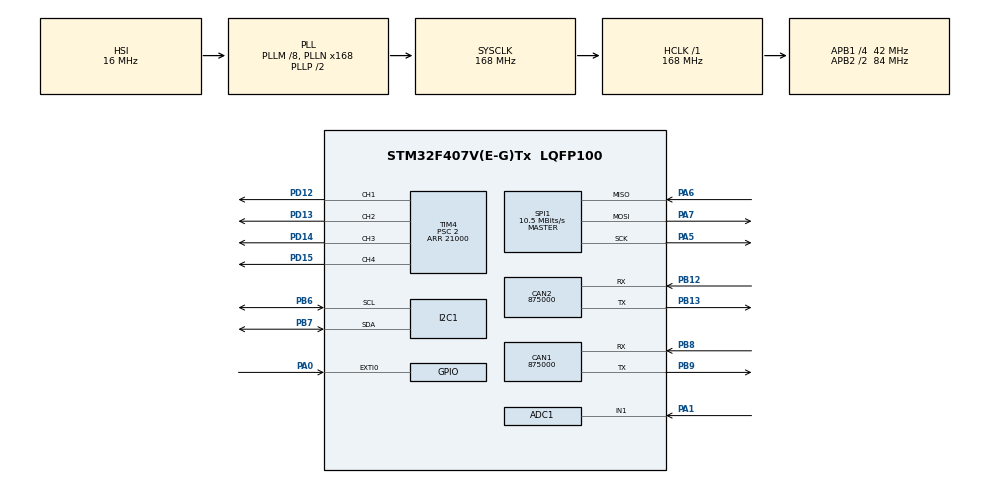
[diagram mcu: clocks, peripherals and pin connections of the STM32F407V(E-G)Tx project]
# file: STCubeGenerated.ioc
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ADC1.Channel-0\#ChannelRegularConversion=ADC_CHANNEL_1
ADC1.NbrOfConversionFlag=1
ADC1.Rank-0\#ChannelRegularConversion=1
ADC1.SamplingTime-0\#ChannelRegularConversion=ADC_SAMPLETIME_3CYCLES
ADC1.master=1
CAN1.BS1=CAN_BS1_1TQ
CAN1.BS2=CAN_BS2_1TQ
CAN1.CalculateBaudRate=875000
CAN1.CalculateTimeBit=1142.85
CAN1.CalculateTimeQuantum=380.95238095238096
CAN2.BS1=CAN_BS1_1TQ
CAN2.BS2=CAN_BS2_1TQ
CAN2.CalculateBaudRate=875000
CAN2.CalculateTimeBit=1142.85
CAN2.CalculateTimeQuantum=380.95238095238096
Mcu.Family=STM32F4
Mcu.Name=STM32F407V(E-G)Tx
Mcu.Package=LQFP100
NVIC.CAN1_RX0_IRQn=true\:0\:0\:false\:false\:true\:true\:true
NVIC.CAN1_RX1_IRQn=true\:0\:0\:false\:false\:true\:true\:true
NVIC.CAN2_RX0_IRQn=true\:0\:0\:false\:false\:true\:true\:true
NVIC.CAN2_RX1_IRQn=true\:0\:0\:false\:false\:true\:true\:true
NVIC.EXTI0_IRQn=true\:0\:0\:false\:false\:true\:true\:true
NVIC.PriorityGroup=NVIC_PRIORITYGROUP_4
PA0-WKUP.Signal=GPXTI0
PA1.Signal=ADCx_IN1
PA5.Mode=Full_Duplex_Master
PA5.Signal=SPI1_SCK
PA6.Mode=Full_Duplex_Master
PA6.Signal=SPI1_MISO
PA7.Mode=Full_Duplex_Master
PA7.Signal=SPI1_MOSI
PB12.Mode=CAN_Activate
PB12.Signal=CAN2_RX
PB13.Mode=CAN_Activate
PB13.Signal=CAN2_TX
PB6.Mode=I2C
PB6.Signal=I2C1_SCL
PB7.Mode=I2C
PB7.Signal=I2C1_SDA
PB8.Mode=CAN_Activate
PB8.Signal=CAN1_RX
PB9.Mode=CAN_Activate
PB9.Signal=CAN1_TX
PD12.Signal=S_TIM4_CH1
PD13.Signal=S_TIM4_CH2
PD14.Signal=S_TIM4_CH3
PD15.Signal=S_TIM4_CH4
ProjectManager.HeapSize=0x200
ProjectManager.StackSize=0x400
ProjectManager.TargetToolchain=MDK-ARM V5
RCC.48MHZClocksFreq_Value=84000000
RCC.AHBFreq_Value=168000000
RCC.APB1CLKDivider=RCC_HCLK_DIV4
RCC.APB1Freq_Value=42000000
RCC.APB1TimFreq_Value=84000000
RCC.APB2CLKDivider=RCC_HCLK_DIV2
RCC.APB2Freq_Value=84000000
RCC.APB2TimFreq_Value=168000000
RCC.CortexFreq_Value=168000000
RCC.HCLKFreq_Value=168000000
RCC.HSE_VALUE=25000000
RCC.HSI_VALUE=16000000
RCC.LSE_VALUE=32768
RCC.PLLM=8
RCC.PLLN=168
RCC.SYSCLKFreq_VALUE=168000000
RCC.SYSCLKSource=RCC_SYSCLKSOURCE_PLLCLK
RCC.VCOOutputFreq_Value=336000000
SH.ADCx_IN1.0=ADC1_IN1,IN1
SH.S_TIM4_CH1.0=TIM4_CH1,PWM Generation1 CH1
SH.S_TIM4_CH2.0=TIM4_CH2,PWM Generation2 CH2
SH.S_TIM4_CH3.0=TIM4_CH3,PWM Generation3 CH3
SH.S_TIM4_CH4.0=TIM4_CH4,Output Compare4 CH4
SPI1.BaudRatePrescaler=SPI_BAUDRATEPRESCALER_8
SPI1.CalculateBaudRate=10.5 MBits/s
SPI1.Direction=SPI_DIRECTION_2LINES
SPI1.Mode=SPI_MODE_MASTER
SPI1.VirtualType=VM_MASTER
TIM4.Channel-Output\ Compare4\ CH4=TIM_CHANNEL_4
TIM4.Channel-PWM\ Generation1\ CH1=TIM_CHANNEL_1
TIM4.Channel-PWM\ Generation2\ CH2=TIM_CHANNEL_2
TIM4.Channel-PWM\ Generation3\ CH3=TIM_CHANNEL_3
TIM4.Period=21000
TIM4.Prescaler=2
board=custom

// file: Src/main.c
/* USER CODE BEGIN Header */
/**
  ******************************************************************************
  * @file           : main.c
  * @brief          : Main program body
  ******************************************************************************
  * @attention
  *
  * <h2><center>&copy; Copyright (c) 2021 STMicroelectronics.
  * All rights reserved.</center></h2>
  *
  * This software component is licensed by ST under BSD 3-Clause license,
  * the "License"; You may not use this file except in compliance with the
  * License. You may obtain a copy of the License at:
  *                        opensource.org/licenses/BSD-3-Clause
  *
  ******************************************************************************
  */
/* USER CODE END Header */
#include "main.h"

/* USER CODE BEGIN Includes */
#include "HWDef.h"

/* USER CODE END Includes */

static ADC_HandleTypeDef hadc1;

static CAN_HandleTypeDef hcan1;
static CAN_HandleTypeDef hcan2;

static I2C_HandleTypeDef hi2c1;

static SPI_HandleTypeDef hspi1;

static TIM_HandleTypeDef htim4;

void SystemClock_Config(void);
static void MX_GPIO_Init(void);
static void MX_ADC1_Init(void);
static void MX_CAN1_Init(void);
static void MX_CAN2_Init(void);
static void MX_I2C1_Init(void);
static void MX_SPI1_Init(void);
static void MX_TIM4_Init(void);

/* USER CODE BEGIN 0 */
void app_main(void *argument) {

  while (1)
    ;
}

/* USER CODE END 0 */

int main(void)
{

  /* MCU Configuration--------------------------------------------------------*/

  /* Reset of all peripherals, Initializes the Flash interface and the Systick. */
  HAL_Init();

  /* Configure the system clock */
  SystemClock_Config();

  /* USER CODE BEGIN SysInit */
	osKernelInitialize();                 // Initialize CMSIS-RTOS
  osThreadNew(app_main, NULL, NULL);    // Create application main thread
	osThreadSetPriority(app_main,osPriorityNormal);
  osKernelStart();

  /* USER CODE END SysInit */

  /* Initialize all configured peripherals */
  MX_GPIO_Init();
  MX_ADC1_Init();
  MX_CAN1_Init();
  MX_CAN2_Init();
  MX_I2C1_Init();
  MX_SPI1_Init();
  MX_TIM4_Init();

  /* Infinite loop */
  while (1)
  {

  }
}

void SystemClock_Config(void)
{
  RCC_OscInitTypeDef RCC_OscInitStruct = {0};
  RCC_ClkInitTypeDef RCC_ClkInitStruct = {0};

  /** Configure the main internal regulator output voltage
  */
  __HAL_RCC_PWR_CLK_ENABLE();
  __HAL_PWR_VOLTAGESCALING_CONFIG(PWR_REGULATOR_VOLTAGE_SCALE1);
  /** Initializes the RCC Oscillators according to the specified parameters
  * in the RCC_OscInitTypeDef structure.
  */
  RCC_OscInitStruct.OscillatorType = RCC_OSCILLATORTYPE_HSI;
  RCC_OscInitStruct.HSIState = RCC_HSI_ON;
  RCC_OscInitStruct.HSICalibrationValue = RCC_HSICALIBRATION_DEFAULT;
  RCC_OscInitStruct.PLL.PLLState = RCC_PLL_ON;
  RCC_OscInitStruct.PLL.PLLSource = RCC_PLLSOURCE_HSI;
  RCC_OscInitStruct.PLL.PLLM = 8;
  RCC_OscInitStruct.PLL.PLLN = 168;
  RCC_OscInitStruct.PLL.PLLP = RCC_PLLP_DIV2;
  RCC_OscInitStruct.PLL.PLLQ = 4;
  if (HAL_RCC_OscConfig(&RCC_OscInitStruct) != HAL_OK)
  {
    Error_Handler();
  }
  /** Initializes the CPU, AHB and APB buses clocks
  */
  RCC_ClkInitStruct.ClockType = RCC_CLOCKTYPE_HCLK|RCC_CLOCKTYPE_SYSCLK
                              |RCC_CLOCKTYPE_PCLK1|RCC_CLOCKTYPE_PCLK2;
  RCC_ClkInitStruct.SYSCLKSource = RCC_SYSCLKSOURCE_PLLCLK;
  RCC_ClkInitStruct.AHBCLKDivider = RCC_SYSCLK_DIV1;
  RCC_ClkInitStruct.APB1CLKDivider = RCC_HCLK_DIV4;
  RCC_ClkInitStruct.APB2CLKDivider = RCC_HCLK_DIV2;

  if (HAL_RCC_ClockConfig(&RCC_ClkInitStruct, FLASH_LATENCY_5) != HAL_OK)
  {
    Error_Handler();
  }
}

static void MX_ADC1_Init(void)
{

  ADC_ChannelConfTypeDef sConfig = {0};

  /** Configure the global features of the ADC (Clock, Resolution, Data Alignment and number of conversion)
  */
  hadc1.Instance = ADC1;
  hadc1.Init.ClockPrescaler = ADC_CLOCK_SYNC_PCLK_DIV4;
  hadc1.Init.Resolution = ADC_RESOLUTION_12B;
  hadc1.Init.ScanConvMode = DISABLE;
  hadc1.Init.ContinuousConvMode = DISABLE;
  hadc1.Init.DiscontinuousConvMode = DISABLE;
  hadc1.Init.ExternalTrigConvEdge = ADC_EXTERNALTRIGCONVEDGE_NONE;
  hadc1.Init.ExternalTrigConv = ADC_SOFTWARE_START;
  hadc1.Init.DataAlign = ADC_DATAALIGN_RIGHT;
  hadc1.Init.NbrOfConversion = 1;
  hadc1.Init.DMAContinuousRequests = DISABLE;
  hadc1.Init.EOCSelection = ADC_EOC_SINGLE_CONV;
  if (HAL_ADC_Init(&hadc1) != HAL_OK)
  {
    Error_Handler();
  }
  /** Configure for the selected ADC regular channel its corresponding rank in the sequencer and its sample time.
  */
  sConfig.Channel = ADC_CHANNEL_1;
  sConfig.Rank = 1;
  sConfig.SamplingTime = ADC_SAMPLETIME_3CYCLES;
  if (HAL_ADC_ConfigChannel(&hadc1, &sConfig) != HAL_OK)
  {
    Error_Handler();
  }

}

static void MX_CAN1_Init(void)
{

  hcan1.Instance = CAN1;
  hcan1.Init.Prescaler = 16;
  hcan1.Init.Mode = CAN_MODE_NORMAL;
  hcan1.Init.SyncJumpWidth = CAN_SJW_1TQ;
  hcan1.Init.TimeSeg1 = CAN_BS1_1TQ;
  hcan1.Init.TimeSeg2 = CAN_BS2_1TQ;
  hcan1.Init.TimeTriggeredMode = DISABLE;
  hcan1.Init.AutoBusOff = DISABLE;
  hcan1.Init.AutoWakeUp = DISABLE;
  hcan1.Init.AutoRetransmission = DISABLE;
  hcan1.Init.ReceiveFifoLocked = DISABLE;
  hcan1.Init.TransmitFifoPriority = DISABLE;
  if (HAL_CAN_Init(&hcan1) != HAL_OK)
  {
    Error_Handler();
  }

}

static void MX_CAN2_Init(void)
{

  hcan2.Instance = CAN2;
  hcan2.Init.Prescaler = 16;
  hcan2.Init.Mode = CAN_MODE_NORMAL;
  hcan2.Init.SyncJumpWidth = CAN_SJW_1TQ;
  hcan2.Init.TimeSeg1 = CAN_BS1_1TQ;
  hcan2.Init.TimeSeg2 = CAN_BS2_1TQ;
  hcan2.Init.TimeTriggeredMode = DISABLE;
  hcan2.Init.AutoBusOff = DISABLE;
  hcan2.Init.AutoWakeUp = DISABLE;
  hcan2.Init.AutoRetransmission = DISABLE;
  hcan2.Init.ReceiveFifoLocked = DISABLE;
  hcan2.Init.TransmitFifoPriority = DISABLE;
  if (HAL_CAN_Init(&hcan2) != HAL_OK)
  {
    Error_Handler();
  }

}

static void MX_I2C1_Init(void)
{

  hi2c1.Instance = I2C1;
  hi2c1.Init.ClockSpeed = 100000;
  hi2c1.Init.DutyCycle = I2C_DUTYCYCLE_2;
  hi2c1.Init.OwnAddress1 = 0;
  hi2c1.Init.AddressingMode = I2C_ADDRESSINGMODE_7BIT;
  hi2c1.Init.DualAddressMode = I2C_DUALADDRESS_DISABLE;
  hi2c1.Init.OwnAddress2 = 0;
  hi2c1.Init.GeneralCallMode = I2C_GENERALCALL_DISABLE;
  hi2c1.Init.NoStretchMode = I2C_NOSTRETCH_DISABLE;
  if (HAL_I2C_Init(&hi2c1) != HAL_OK)
  {
    Error_Handler();
  }

}

static void MX_SPI1_Init(void)
{

  /* SPI1 parameter configuration*/
  hspi1.Instance = SPI1;
  hspi1.Init.Mode = SPI_MODE_MASTER;
  hspi1.Init.Direction = SPI_DIRECTION_2LINES;
  hspi1.Init.DataSize = SPI_DATASIZE_8BIT;
  hspi1.Init.CLKPolarity = SPI_POLARITY_LOW;
  hspi1.Init.CLKPhase = SPI_PHASE_1EDGE;
  hspi1.Init.NSS = SPI_NSS_SOFT;
  hspi1.Init.BaudRatePrescaler = SPI_BAUDRATEPRESCALER_8;
  hspi1.Init.FirstBit = SPI_FIRSTBIT_MSB;
  hspi1.Init.TIMode = SPI_TIMODE_DISABLE;
  hspi1.Init.CRCCalculation = SPI_CRCCALCULATION_DISABLE;
  hspi1.Init.CRCPolynomial = 10;
  if (HAL_SPI_Init(&hspi1) != HAL_OK)
  {
    Error_Handler();
  }

}

static void MX_TIM4_Init(void)
{

  TIM_MasterConfigTypeDef sMasterConfig = {0};
  TIM_OC_InitTypeDef sConfigOC = {0};

  htim4.Instance = TIM4;
  htim4.Init.Prescaler = 2;
  htim4.Init.CounterMode = TIM_COUNTERMODE_UP;
  htim4.Init.Period = 21000;
  htim4.Init.ClockDivision = TIM_CLOCKDIVISION_DIV1;
  htim4.Init.AutoReloadPreload = TIM_AUTORELOAD_PRELOAD_DISABLE;
  if (HAL_TIM_PWM_Init(&htim4) != HAL_OK)
  {
    Error_Handler();
  }
  if (HAL_TIM_OC_Init(&htim4) != HAL_OK)
  {
    Error_Handler();
  }
  sMasterConfig.MasterOutputTrigger = TIM_TRGO_RESET;
  sMasterConfig.MasterSlaveMode = TIM_MASTERSLAVEMODE_DISABLE;
  if (HAL_TIMEx_MasterConfigSynchronization(&htim4, &sMasterConfig) != HAL_OK)
  {
    Error_Handler();
  }
  sConfigOC.OCMode = TIM_OCMODE_PWM1;
  sConfigOC.Pulse = 0;
  sConfigOC.OCPolarity = TIM_OCPOLARITY_HIGH;
  sConfigOC.OCFastMode = TIM_OCFAST_DISABLE;
  if (HAL_TIM_PWM_ConfigChannel(&htim4, &sConfigOC, TIM_CHANNEL_1) != HAL_OK)
  {
    Error_Handler();
  }
  if (HAL_TIM_PWM_ConfigChannel(&htim4, &sConfigOC, TIM_CHANNEL_2) != HAL_OK)
  {
    Error_Handler();
  }
  if (HAL_TIM_PWM_ConfigChannel(&htim4, &sConfigOC, TIM_CHANNEL_3) != HAL_OK)
  {
    Error_Handler();
  }
  sConfigOC.OCMode = TIM_OCMODE_TIMING;
  if (HAL_TIM_OC_ConfigChannel(&htim4, &sConfigOC, TIM_CHANNEL_4) != HAL_OK)
  {
    Error_Handler();
  }
  HAL_TIM_MspPostInit(&htim4);

}

static void MX_GPIO_Init(void)
{
  GPIO_InitTypeDef GPIO_InitStruct = {0};

  /* GPIO Ports Clock Enable */
  __HAL_RCC_GPIOA_CLK_ENABLE();
  __HAL_RCC_GPIOB_CLK_ENABLE();
  __HAL_RCC_GPIOD_CLK_ENABLE();

  /*Configure GPIO pin : PA0 */
  GPIO_InitStruct.Pin = GPIO_PIN_0;
  GPIO_InitStruct.Mode = GPIO_MODE_IT_RISING;
  GPIO_InitStruct.Pull = GPIO_NOPULL;
  HAL_GPIO_Init(GPIOA, &GPIO_InitStruct);

  /* EXTI interrupt init*/
  HAL_NVIC_SetPriority(EXTI0_IRQn, 0, 0);
  HAL_NVIC_EnableIRQ(EXTI0_IRQn);

}

void Error_Handler(void)
{
  __disable_irq();
  while (1)
  {
  }
}

/************************ (C) COPYRIGHT STMicroelectronics *****END OF FILE****/
